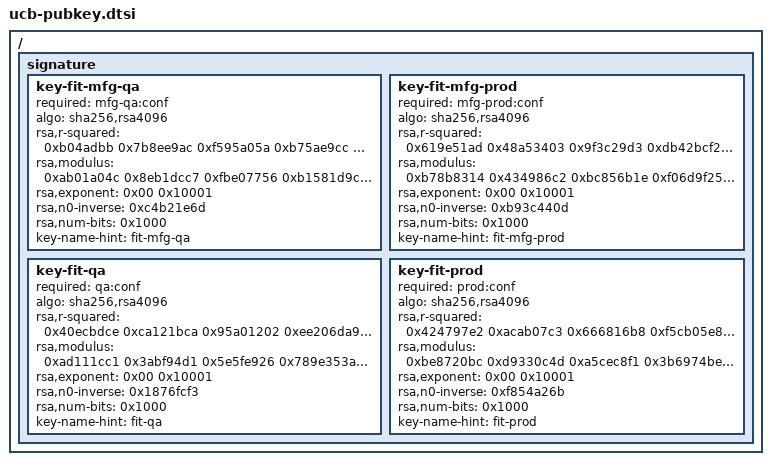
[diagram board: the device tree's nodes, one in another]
/*
 * This is a Device Tree representation of the public keys that will
 * be used for FIT image verification.
 *
 * The procedure to generate this file from production keys in AWS CloudHSM is
 * avaliable here:
 * https://github.com/ChargePoint/emb-platform/blob/master/os/buildroot/package/emb-sbsigner/README.md
 */

/ {

	signature {

		key-fit-mfg-qa {
			required = "mfg-qa:conf";
			algo = "sha256,rsa4096";
			rsa,r-squared = < 0xb04adbb 0x7b8ee9ac 0xf595a05a 0xb75ae9cc 0x8565778f 0x6a215ddb 0xba9c04f2 0x96cb33e5 0x5fc77768 0xcbc983eb 0x9ea4cb87 0x155cfe7b 0x71184b4a 0xf25593ad 0xc82d842e 0xfafc7d41 0x33417b5a 0x4670aff0 0x67f07bc4 0x3c77abdf 0xe5880ca 0x2469c165 0xe750d74 0x46e874df 0x77dda5ce 0xfeb4903c 0x10153448 0x6dd5821f 0x84fa46bd 0x40412bd9 0x320d90c7 0x65b4eb10 0x9da808c2 0xfae4e823 0x21d18d15 0xb6782e09 0x5aaeec64 0x8e234d15 0x99cb3623 0xa11bb07d 0xb001e49e 0x9c5c50e8 0xd88fca4f 0x2080a56f 0x35d26d09 0x308449fd 0xa650c32c 0x3df4802e 0xca7614e1 0xaaf580fb 0x4c08414b 0x65ccfa3 0xaebae632 0x45952f6d 0xcab3e39e 0xdef3fe0e 0xf65d130 0xde074a4a 0x59875410 0xe226f1b5 0x7c43dc41 0x568bcc12 0x225e6c66 0xa1e247d 0x336da5b4 0x8adadebf 0xe9cb8fb9 0x21677d63 0xe5dca988 0xe179e28d 0xc911acbe 0xf86a4a0b 0x555e5846 0x77da5e18 0x9ab7ed57 0x69af71bc 0x66ad8ae6 0x263d4af6 0x61389e0d 0x2fd26100 0xcca64d5c 0xb468b1c1 0x792ffd57 0x18b82ef9 0xe70b3d32 0xb790082a 0x555427e5 0xd51636b 0xd43277fa 0x7881419a 0x5de6f7d6 0xa5eb8c36 0xaf44f4b4 0x48eeb926 0x57b7f709 0xe1aa73fe 0x18af9e90 0x83059036 0x8ce39e51 0x62d40fe3 0x162abb97 0xc1c4d556 0x95a4ec07 0x64589223 0xba96023 0xf4fd655 0x51bf8f7b 0x7363498f 0x7d815825 0x16fd95ba 0xdfef7f74 0xb0cb7d1d 0x59769fd2 0x93d60147 0x1471dad7 0x9a4eb27b 0x47b2b81f 0x31d01232 0xe05470ae 0xd770c02c 0xea61e887 0x701c9d56 0x362e9e24 0x543e9807 0x220e26c0 0x6b69791d 0xaeccf46e 0x3f937abe >;
			rsa,modulus = < 0xab01a04c 0x8eb1dcc7 0xfbe07756 0xb1581d9c 0xf13a6590 0x9661fdc 0x3a152a7f 0x3b7770e6 0x77b79e8b 0x5058dc90 0x3b5084f0 0xfd8dbbb7 0x7ebd13f0 0xc3bb3308 0x1ae5be67 0x6d832e85 0xf728bfe1 0xfa77b2a 0x840dfca7 0x8048f4c 0xc394cbe0 0xc8cc00e9 0xd6bc3dfb 0x19fe5210 0x234680eb 0x52049433 0x9dac5833 0x4c10815 0xf0230a36 0x4300df32 0x1e2d6f5c 0x281358cc 0xbbfee883 0x722e6b5c 0xe2e147af 0x89bf6c9e 0xba8eb4f5 0x734ae6e9 0xffb649b2 0x1985c278 0x442d9376 0x537000bc 0x1175cf29 0x7540ae32 0xaaec5d84 0xa2383bf5 0xec964de6 0xc0b6dda 0xff5ba0a5 0x581d9803 0x9b74ef78 0x51068f4a 0xc14d9215 0x75577b52 0x4391e2c4 0xf307e114 0x8c95ccac 0x6c696d28 0xc88dc41a 0x8e9e85da 0x69e7e937 0x5e087a35 0x409cced2 0x2c7253 0xa839bf66 0xf1a0b3f5 0x5d8d5f38 0x66bc176 0x27ecfe4d 0x6040a2c1 0x17fe9287 0x17e19b67 0xe34ae0d3 0xde0d436b 0xb42afd90 0xd7a6188e 0xd1f6e02 0x90034709 0xc33d82f0 0xc9cfa8e5 0x3abe1cda 0x405296a 0xc13483 0x81e37281 0xa8e1a56e 0x8bb92dee 0x91e913f1 0xc3bcaedf 0x5ab8a252 0x8a7d974a 0x5f44b850 0x7449e7c8 0x921d921 0xc84b1e6c 0x7221ba5c 0xa9dd2e10 0x22a3f58c 0x61f98284 0x3bb0342e 0xcb90b1f1 0x3d2eedbe 0x3ad55c45 0xb42ce099 0x809cb675 0x804a08f2 0x83c5c321 0x79c6f68e 0x546b7aca 0x99fae530 0xf821663a 0x4d31ec4d 0xad42cbf4 0xb806516a 0x9a634631 0x4ae3535c 0xeaabb021 0x2bab5985 0xa4594ad8 0x28f3167 0x68aadbe0 0xbdb1aeec 0x3df8890a 0xbb15524c 0x40c529c3 0x1bf66f9b 0x6cd9f8c1 0xe61ac88d 0x639649b >;
			rsa,exponent = < 0x00 0x10001 >;
			rsa,n0-inverse = < 0xc4b21e6d >;
			rsa,num-bits = < 0x1000 >;
			key-name-hint = "fit-mfg-qa";
		};

		key-fit-mfg-prod {
			required = "mfg-prod:conf";
			algo = "sha256,rsa4096";
			rsa,r-squared = < 0x619e51ad 0x48a53403 0x9f3c29d3 0xdb42bcf2 0x5d223f86 0x3f26fc0b 0x1742d994 0x11c00d87 0x6f2b824 0x8345df85 0x546b87ff 0x8f01c90e 0x1129fe5f 0x4ec5e8c2 0x4aabcf1d 0xef88ddb7 0x5cedf914 0xbb4156bb 0x2473bba1 0x31511c21 0x3e01745c 0xba9362f5 0x4867d5fe 0x6abc8dfd 0x870d88ac 0xf4438e28 0x988d73a7 0xfd9550b0 0xcd7a34e3 0x59c60274 0x7d60df37 0x5ec8e740 0xbd50b78 0x4826b05c 0x38b9ede5 0xd6b14260 0xb5e21d1b 0x220b8eab 0xf18bf777 0x9fb34ec 0xf272e084 0xfd0628a3 0x48fbb9d1 0x2d662e9b 0x97d79855 0xcc886f65 0xdf2888c3 0x9b063930 0x3a3e63bb 0xfe71f7e6 0x6d4bd954 0x3a6fe05a 0xf1b84412 0x57dc7a5a 0xee377318 0x50b4892 0x2b763c60 0xaf99870f 0xee342a0a 0x34bd2e20 0xef662612 0xd72d09e4 0xf5eecd29 0x993a8ecd 0x8f4b9e1b 0x657a3634 0xc0bb0b3b 0xa73e8885 0xce07ed17 0x2f728a14 0xa9f2f532 0x97fb28fd 0xbdae6009 0x8584e3bf 0x98fa564b 0x6c5e29fa 0x2d6393c9 0xb2e1a0f6 0xea9871d3 0x3b757531 0x6e7da03f 0x58a1707a 0x98bc505 0x1f336aaf 0xd11e1078 0xd4f8b86a 0xe88beafc 0xdd8a3b7c 0xa233b4c6 0x3ac383c9 0xc5f37ab1 0x54f297b0 0x461af8e2 0x7b0cc8d2 0xe2dc885c 0x8c3861f2 0xb4171ea0 0x3f382913 0x475a3243 0xf6da1e0d 0xa2e6c0f7 0xd8187dc2 0x35762845 0x4cc75bf2 0x2e19c1b2 0x130fa5da 0x1c01c4c7 0x63226302 0xe54dc3dc 0xe50a2278 0x7568211a 0xecfa15f9 0x8dc30a2e 0x3d630afe 0x1067a38d 0xb9ef37e2 0x4f1bf6fe 0x47d3f8af 0xe03a4af5 0x9bae5e39 0xbe66d433 0x6cf8d3fd 0x72507d39 0x159989aa 0x94270fbb 0xa157333d 0x1816a438 0x4874df48 >;
			rsa,modulus = < 0xb78b8314 0x434986c2 0xbc856b1e 0xf06d9f25 0x6eaefb3f 0x3a10a9d5 0xeaede66f 0x181850f4 0x339ef44e 0x4f2e86cc 0x7b4fb5de 0xc038426e 0x3da2bded 0x51a189d 0x52455cce 0x838b910f 0x5813377a 0xb105fb1b 0xee6ebd63 0x963f7ebe 0xa9e96546 0xf7c8f145 0xd7f7b769 0xfc103a52 0xff1672fa 0x7c6ca631 0xc9959eb 0x81b564fb 0x8dbf8dc 0x3eca86bc 0xbacd25c9 0x8e5d1213 0xe8d0e34d 0x1395fd5e 0xb40a4b1b 0x8c201b20 0x8016807d 0x23fb0101 0xb6610439 0x74979043 0x3fc8aa27 0xb7586a1e 0xd166307a 0x2ac9bb4a 0x4d7ddc12 0x7140239f 0x2d0410e9 0xff13d1b 0xc940a974 0x5f2c4e56 0x43406dbf 0x86cca607 0x3c98a846 0x3909c199 0xdcc60e95 0xb5942e8b 0x8e487596 0xa7b91a56 0x5836a086 0xaa1edb3 0x8367e38 0x9c9d7088 0xa6505177 0xe40e830b 0xfc3d4e71 0x752e858c 0xf32f5b33 0xc2078919 0xc585cc73 0xafe45c29 0x24b394a0 0x2e77959e 0xe8afdc6e 0x53564113 0xebc80596 0xf5bcab80 0xa32e8f0e 0x4ac96854 0xeb876bb8 0x236b31fa 0xe6bf31b3 0x770aae98 0x28965a74 0xe85978e5 0xdc5ab217 0x25b418dc 0xb1c9b034 0xfd6c53f8 0x19c70bfa 0xa520a788 0x29bb7ab0 0xffbf8f5a 0xeb229e03 0xe257b132 0xbdfdba1f 0xef98b0e3 0x8a2a7832 0x8efa98af 0x3c04d372 0x828b3c41 0x24536ce8 0x678a810c 0x3dc56df2 0x1c99ad7c 0xcf80dbf3 0x2125c501 0x5af1845e 0x13a5033 0xc10a216c 0x43e1273e 0x9adb8d1a 0xba7296b 0x55b362fd 0xa567d10 0xa54295d0 0xaff0b8cc 0x92d185b6 0x3358f07e 0xb74622e2 0x84dcde01 0x877d58f4 0x4fdab3c7 0xf961d410 0x8f12ff8e 0x9b6b3d5f 0xc9da62df 0xbab51ed 0x8994553b >;
			rsa,exponent = < 0x00 0x10001 >;
			rsa,n0-inverse = < 0xb93c440d >;
			rsa,num-bits = < 0x1000 >;
			key-name-hint = "fit-mfg-prod";
		};

		key-fit-qa {
			required = "qa:conf";
			algo = "sha256,rsa4096";
			rsa,r-squared = < 0x40ecbdce 0xca121bca 0x95a01202 0xee206da9 0x8656b680 0xfcf96c55 0x14b812e9 0xd0beca0b 0x12e7222c 0xec53019f 0x44ed4578 0x9914d342 0xb42f584f 0x1d972d30 0x5599b6fd 0x6a858da3 0xa0605234 0xc4ff3d3a 0x1fe139e9 0xa289cf10 0x7d8e9e5d 0x3437b8fa 0xe47c991 0xdde8f822 0xbdab610 0xc0401106 0xd0284ef5 0x2cf470c3 0x70293a28 0x950571c6 0xbe05e3e4 0x8ad3b806 0x6c250d80 0x586e357c 0xbfeb94aa 0xf7535e4d 0xb54e87f4 0xae2c35e8 0xad936bbc 0xf2df85d1 0xa8539687 0x8c40a0cc 0x2b58c3a1 0x660ab02c 0xc150d9da 0xbe004d22 0x8f10dada 0x41186ca4 0xed1b1da1 0xa0e501b2 0xb7fb56d4 0x3cd803a1 0xb63cbcfd 0xaf3854ea 0xa90adb2b 0xb35a7b8e 0x25c0692 0x1837b560 0x9ecbd0c0 0xb050b125 0xd32accde 0x367eec55 0x978dcec 0xe7296614 0xc380f9c8 0xf836aa70 0xd9c3dba7 0x37f9198 0xe9a90dff 0x18f8f4a5 0xf3d18c1c 0x2b94f3 0xb52b2b1f 0x32397901 0x6e2822cc 0x26c16cf5 0xddf20c0c 0x1c1f0d61 0xfe1c8a22 0x96df478f 0xf5066021 0x317f0e8a 0xb4e94e1a 0xc4a4fe20 0x91c9c913 0xcf322e2b 0xf6d702e9 0x1bbe2bef 0x47d9df18 0xeb920a10 0xc775b0e4 0xe8a25741 0x99b3a182 0x124c6d96 0xe80b480b 0x31264f83 0x80cbcf08 0x635aaa9c 0x28a46bf4 0xc7fc8ded 0x207e2869 0xde5a7fc0 0x6af75dee 0x9b59003c 0x925abfeb 0xcec0419a 0x4fced057 0x771a7ce5 0x3cf074f5 0x59aa151f 0x5ad7628c 0x5552a705 0xb4362d37 0x4999f34e 0x26f900c5 0xc12a013d 0x227c0795 0x1597df95 0xa9faefd0 0x4d40fb4d 0x6d38c1ea 0x32c082e8 0xee2dc57 0xf34bd9da 0xecd6cba 0x8662142 0xf24e2c2a 0x8910a37a >;
			rsa,modulus = < 0xad111cc1 0x3abf94d1 0x5e5fe926 0x789e353a 0x6881d210 0x7ece863b 0x164d8b9d 0xb8ee3edb 0xa3b43a43 0x35d58e38 0x4cdd6580 0x25e1d502 0x755c152d 0xa4e2723d 0xa545e870 0xfe9097a3 0x184d5471 0x36e6a768 0xd949dd5 0xa0d7d67c 0x9eb0b284 0xa7beb357 0xcd6a4354 0x60bc7795 0x9f0089f9 0xf7f71f1d 0xb598d543 0xe4fff238 0xb81f2c99 0x6b06853c 0xeaa6bf24 0x7be19b4d 0x2c0ef3eb 0xb48d670d 0xa9304ae1 0x7e7cb5dc 0x657c0085 0xa5317327 0xe557cccb 0xfca287bc 0x471d9f1c 0x47d4cf4f 0xb2ed6476 0x6c87c55a 0x827aaac0 0xb09597fa 0xa3a7e397 0x17460b2f 0xadada4db 0x218aac67 0xe06058f2 0x50ef4085 0xb2dcb0b3 0x838d6bfc 0x1c73965a 0x5943301f 0x70ebabc7 0x6ea1cfc 0x955b08f1 0x6035c3d3 0x1acb902d 0x50233920 0xcc3e59e5 0x9e331c0 0x43929062 0x1bf33b6 0xf8eced82 0x3782dd46 0xcd2ded3b 0x3ee5f2d2 0x1eb5bd9b 0x4e8512a6 0x681e956 0x3df71b33 0xecf047bf 0x9ddefb0a 0x11e218be 0x22c12425 0xca89fd2c 0xd24c0099 0x5cdd4ddc 0xbccdcfbc 0x8933052f 0x9525c28f 0x13524dbc 0xcfc52fe4 0xeb6255e9 0xdf4a581d 0x7f93b861 0x3d5226b9 0x79f812cf 0x1cf18e2c 0xdf0dd85c 0x35b81222 0x339adcf1 0xf9e73212 0xc94d1cd2 0xff3d6c56 0xcb5f6fd2 0xff47a47b 0x1834edab 0x18c2d092 0x6275d933 0xae346e75 0x2592797c 0xbadfeb2b 0xe0eac5fc 0x86c18dbb 0xbc4ba324 0x3d101c42 0x818bd2ec 0x7474391 0x51c2e742 0xc31f194d 0x1c610729 0xd444024d 0x32925b96 0x63d090dd 0xf72da0a7 0x35e4a11b 0x3062bf30 0x60037d0c 0x94f9c0b6 0x6cd9497d 0xd1e27f5e 0x5ef0adca 0x27cac9b2 0x56c583c5 >;
			rsa,exponent = < 0x00 0x10001 >;
			rsa,n0-inverse = < 0x1876fcf3 >;
			rsa,num-bits = < 0x1000 >;
			key-name-hint = "fit-qa";
		};

		key-fit-prod {
			required = "prod:conf";
			algo = "sha256,rsa4096";
			rsa,r-squared = < 0x424797e2 0xacab07c3 0x666816b8 0xf5cb05e8 0x8bb0009e 0x5e9ffb89 0xe41772b2 0x8019061b 0xe301e3f0 0xf9d37d7 0xe5e8fe30 0x4a8717f8 0xc91a63da 0xdfa1f102 0x37469e72 0x2a701d4f 0xe9fb842c 0x65135bc0 0xa6644159 0xa62f0138 0x59d77267 0x927c78ea 0x23f096a2 0x40988a6c 0xb34808fe 0x6a639105 0x86211119 0xf3d19fc1 0x700c0f8b 0x4d73bbb9 0x6b9b2966 0xb4a9ca0d 0xbff703da 0xcde29e3a 0x5319961b 0xc3722152 0x65c7d25e 0x4f9587f3 0x842ee827 0x217a9d34 0xfed89af2 0x26b4056b 0x8d2811ff 0x1a13a46e 0xca1f3d9b 0xd781a633 0x122ca609 0x53805f99 0xbae070b8 0x3e7ffb2 0x22b1122a 0x5cc133b7 0xdd49f320 0x82f72dd3 0xb21634e7 0x693fbec0 0x503cb6ca 0x550e8bfc 0x7376bc00 0xd8a015e4 0xa2f91d68 0x47727f9f 0xb300ccd4 0x925fe628 0xae1664fd 0x65615600 0xb79fa50a 0x4e388dd2 0x368e52de 0x38a23119 0x8434c67f 0x2de747c6 0x7dff919 0xf22e0e55 0xa094d6e3 0xddd4d4ba 0xa32097dc 0x7622c006 0x50601b20 0x847d2967 0x9d1245e6 0x9d8abf42 0xbf535315 0xa549fabf 0xc5f2de9b 0xe8c49643 0x7a914dde 0xd235d1ea 0x9e9d5dd6 0xfc470d2d 0xb9821e12 0x7009f134 0xacd98c75 0x30ae12d3 0xcd739e53 0x2ac9dff2 0x15fcfb2e 0x3052b534 0xa917ed57 0x2c7c3f6b 0x1f0386f1 0xbfc58811 0x68bf8832 0xe30c11b0 0x56a96a8f 0xff22209d 0x28ebd0f6 0xafa2a69d 0xb8d606cf 0x26067912 0x8b60ad9e 0x64d8fada 0x7875c644 0xa6ce01f0 0x92b36719 0x35b77e98 0xadeeb720 0x90fff35b 0xc7a6a744 0xba193f60 0xdce91a0a 0xe847dcf5 0x3fbff0dd 0xa39cf4a9 0xe131da3c 0x9d62825d 0x9126e554 0x65009c4a >;
			rsa,modulus = < 0xbe8720bc 0xd9330c4d 0xa5cec8f1 0x3b6974be 0x8aea3c94 0x8acbacd0 0x7218da0a 0xe62bdaf0 0xa36d76b7 0x90668ea 0xc17a094f 0xc2f97142 0x5a928987 0x6878a9d5 0x2135bef1 0x11e43a54 0xe3b648cc 0xf48fc959 0xb60243db 0x79829a1e 0xa177b15b 0x993b71f9 0x9d908b46 0x86e4fa9b 0xf58797ab 0x47ea8996 0x8b6e49f3 0x6df48208 0xeb10c907 0x690290f1 0xccacc9cd 0x6fc8f150 0xe834a509 0x3e1175dd 0xef3603f6 0x3ded2aa 0x41366f84 0x4bbd1290 0xa34fb06e 0x31d4bdcf 0x4e2a70e4 0x92a16dbf 0x7dc3ccf0 0xc79a52a3 0xaa9978b7 0x67e045cd 0x5f1df0d8 0x88743746 0x34dd619c 0x9e8b108f 0xf4651d76 0x1ca2857 0x1abc20d7 0x7da63ab8 0xe2057bc3 0x151ee5ab 0xab3dfafa 0x8116606c 0xe8391f7d 0xb141681e 0x1c4a65b7 0x15b5a64d 0x2ce1d35e 0xde42d176 0x8e1bfb0d 0x3b1f0f6f 0xf611e6be 0x218e6431 0xe2711710 0x9ce0e015 0x482c6258 0xa34f00ad 0x90859f5a 0xb7bbc25f 0xfd8cc1ef 0x4b0c05ab 0xbc6d60bf 0x907d2d80 0xa9736c1d 0x6be387dc 0xc09806b8 0xc6b31a90 0x2536ee79 0x5bd6dec9 0x8cfc271e 0x44ca0b3d 0x5bc9893d 0xf68606fe 0x90623a94 0x3b32d66 0x32726998 0x36a50efb 0xb12c0a8d 0x4f7cec81 0xbf492fcc 0x18347b24 0x7ddeabc3 0x424884d7 0xb7c92b72 0x52d5f14f 0x4cfb8ed3 0xfe8358f2 0xece6b577 0x5e04b7eb 0x5ea6cc78 0x9c29acf1 0xaf47f27d 0xbb053a24 0xfd369904 0x78ab8e74 0x49ee205e 0x45bc6722 0x1d9a1391 0x7403bc7e 0x373f31ba 0x19377d3e 0xe2cbc7b2 0x7a088ea1 0x75fb97e8 0xcbc118aa 0x70b28a43 0xd0886a54 0x7056b876 0xdd81f2a3 0x90da58d1 0x8d9a65f0 0x9c8309c0 0x8d0805bd >;
			rsa,exponent = < 0x00 0x10001 >;
			rsa,n0-inverse = < 0xf854a26b >;
			rsa,num-bits = < 0x1000 >;
			key-name-hint = "fit-prod";
		};
	};
};
